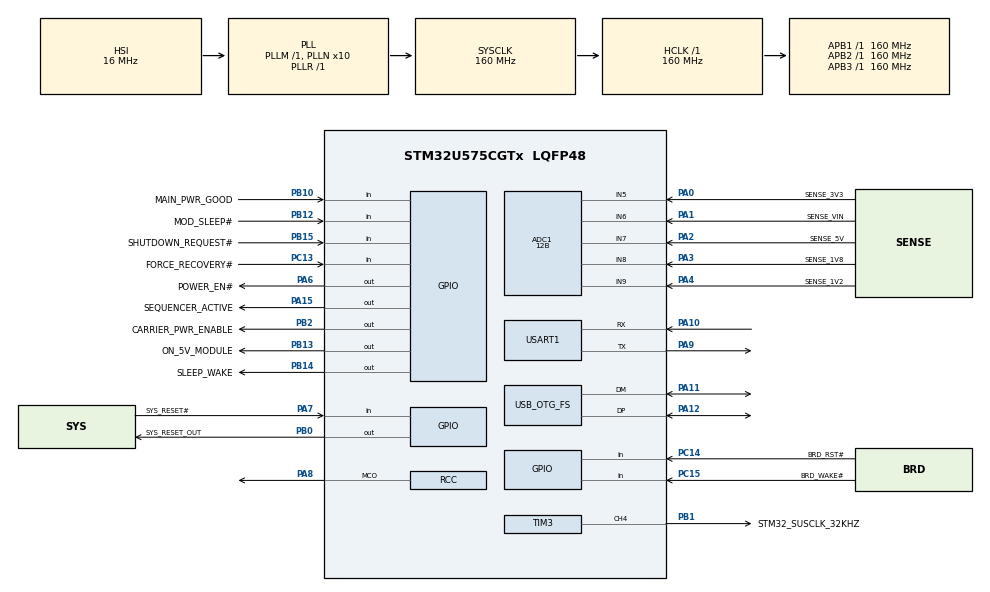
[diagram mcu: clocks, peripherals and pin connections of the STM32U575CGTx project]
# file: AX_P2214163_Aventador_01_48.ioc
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ADC1.Channel-0\#ChannelRegularConversion=ADC_CHANNEL_5
ADC1.Channel-1\#ChannelRegularConversion=ADC_CHANNEL_6
ADC1.Channel-2\#ChannelRegularConversion=ADC_CHANNEL_7
ADC1.Channel-3\#ChannelRegularConversion=ADC_CHANNEL_8
ADC1.Channel-4\#ChannelRegularConversion=ADC_CHANNEL_9
ADC1.ClockPrescaler=ADC_CLOCK_ASYNC_DIV256
ADC1.ContinuousConvMode=DISABLE
ADC1.ConversionDataManagement=ADC_CONVERSIONDATA_DMA_CIRCULAR
ADC1.EOCSelection=ADC_EOC_SEQ_CONV
ADC1.EnableRegularConversion=ENABLE
ADC1.ExternalTrigConv=ADC_EXTERNALTRIG_T6_TRGO
ADC1.MonitoredBy-0\#ChannelRegularConversion=__NULL
ADC1.MonitoredBy-1\#ChannelRegularConversion=__NULL
ADC1.MonitoredBy-2\#ChannelRegularConversion=__NULL
ADC1.MonitoredBy-3\#ChannelRegularConversion=__NULL
ADC1.MonitoredBy-4\#ChannelRegularConversion=__NULL
ADC1.NbrOfConversion=5
ADC1.NbrOfConversionFlag=1
ADC1.OffsetNumber-0\#ChannelRegularConversion=ADC_OFFSET_NONE
ADC1.OffsetNumber-1\#ChannelRegularConversion=ADC_OFFSET_NONE
ADC1.OffsetNumber-2\#ChannelRegularConversion=ADC_OFFSET_NONE
ADC1.OffsetNumber-3\#ChannelRegularConversion=ADC_OFFSET_NONE
ADC1.OffsetNumber-4\#ChannelRegularConversion=ADC_OFFSET_NONE
ADC1.OversamplingMode=ENABLE
ADC1.Rank-0\#ChannelRegularConversion=1
ADC1.Rank-1\#ChannelRegularConversion=2
ADC1.Rank-2\#ChannelRegularConversion=3
ADC1.Rank-3\#ChannelRegularConversion=4
ADC1.Rank-4\#ChannelRegularConversion=5
ADC1.Ratio=8
ADC1.Resolution=ADC_RESOLUTION_12B
ADC1.RightBitShift=ADC_RIGHTBITSHIFT_3
ADC1.SamplingTime-0\#ChannelRegularConversion=ADC_SAMPLETIME_391CYCLES_5
ADC1.SamplingTime-1\#ChannelRegularConversion=ADC_SAMPLETIME_391CYCLES_5
ADC1.SamplingTime-2\#ChannelRegularConversion=ADC_SAMPLETIME_391CYCLES_5
ADC1.SamplingTime-3\#ChannelRegularConversion=ADC_SAMPLETIME_391CYCLES_5
ADC1.SamplingTime-4\#ChannelRegularConversion=ADC_SAMPLETIME_391CYCLES_5
ADC1.master=1
CORTEX_M33_NS.userName=CORTEX_M33
GPDMA1.CIRCULARMODE_GPDMACH0=ENABLE
GPDMA1.DESTDATAWIDTH_GPDMACH0=DMA_DEST_DATAWIDTH_HALFWORD
GPDMA1.DESTINC_GPDMACH0=DMA_DINC_INCREMENTED
GPDMA1.DIRECTION_GPDMACH2=DMA_MEMORY_TO_PERIPH
GPDMA1.IPHANDLE_GPDMACH0-SIMPLEREQUEST_GPDMACH0=__NULL
GPDMA1.IPHANDLE_GPDMACH1-SIMPLEREQUEST_GPDMACH1=__NULL
GPDMA1.IPHANDLE_GPDMACH2-SIMPLEREQUEST_GPDMACH2=__NULL
GPDMA1.REQUEST_GPDMACH0=GPDMA1_REQUEST_ADC1
GPDMA1.REQUEST_GPDMACH1=GPDMA1_REQUEST_USART1_RX
GPDMA1.REQUEST_GPDMACH2=GPDMA1_REQUEST_USART1_TX
GPDMA1.SRCDATAWIDTH_GPDMACH0=DMA_SRC_DATAWIDTH_HALFWORD
GPDMA1.TRANSFERALLOCATEDPORTDEST_GPDMACH2=DMA_DEST_ALLOCATED_PORT1
GPDMA1.TRANSFERALLOCATEDPORTSRC_GPDMACH0=DMA_SRC_ALLOCATED_PORT1
Mcu.Family=STM32U5
Mcu.Name=STM32U575CGTx
Mcu.Package=LQFP48
NVIC.GPDMA1_Channel0_IRQn=true\:0\:0\:false\:false\:true\:false\:true\:true
NVIC.GPDMA1_Channel1_IRQn=true\:0\:0\:false\:false\:true\:false\:true\:true
NVIC.GPDMA1_Channel2_IRQn=true\:0\:0\:false\:false\:true\:false\:true\:true
NVIC.OTG_FS_IRQn=true\:0\:0\:false\:false\:true\:true\:true\:true
NVIC.PriorityGroup=NVIC_PRIORITYGROUP_4
NVIC.TIM6_IRQn=true\:0\:0\:false\:false\:true\:true\:true\:true
NVIC.TIM7_IRQn=true\:0\:0\:false\:false\:true\:true\:true\:true
NVIC.USART1_IRQn=true\:0\:0\:false\:false\:true\:true\:true\:true
PA0.GPIO_Label=SENSE_3V3
PA0.Mode=IN5-Single-Ended
PA0.Signal=ADC1_IN5
PA1.GPIO_Label=SENSE_VIN
PA1.Mode=IN6-Single-Ended
PA1.Signal=ADC1_IN6
PA10.Mode=Asynchronous
PA10.Signal=USART1_RX
PA11.Mode=Device_Only
PA11.Signal=USB_OTG_FS_DM
PA12.Mode=Device_Only
PA12.Signal=USB_OTG_FS_DP
PA13\ (JTMS/SWDIO).Mode=Serial_Wire
PA13\ (JTMS/SWDIO).Signal=DEBUG_JTMS-SWDIO
PA14\ (JTCK/SWCLK).Mode=Serial_Wire
PA14\ (JTCK/SWCLK).Signal=DEBUG_JTCK-SWCLK
PA15\ (JTDI).GPIO_Label=SEQUENCER_ACTIVE
PA15\ (JTDI).Signal=GPIO_Output
PA2.GPIO_Label=SENSE_5V
PA2.Mode=IN7-Single-Ended
PA2.Signal=ADC1_IN7
PA3.GPIO_Label=SENSE_1V8
PA3.Mode=IN8-Single-Ended
PA3.Signal=ADC1_IN8
PA4.GPIO_Label=SENSE_1V2
PA4.Mode=IN9-Single-Ended
PA4.Signal=ADC1_IN9
PA6.GPIO_Label=POWER_EN\#
PA6.PinState=GPIO_PIN_SET
PA6.Signal=GPIO_Output
PA7.GPIO_Label=SYS_RESET\#
PA7.Signal=GPIO_Input
PA8.Mode=Clock-out
PA8.Signal=RCC_MCO
PA9.Mode=Asynchronous
PA9.Signal=USART1_TX
PB0.GPIO_Label=SYS_RESET_OUT
PB0.Signal=GPIO_Output
PB1.GPIO_Label=STM32_SUSCLK_32KHZ
PB1.Signal=S_TIM3_CH4
PB10.GPIO_Label=MAIN_PWR_GOOD
PB10.GPIO_PuPd=GPIO_PULLUP
PB10.Signal=GPIO_Input
PB12.GPIO_Label=MOD_SLEEP\#
PB12.GPIO_PuPd=GPIO_PULLDOWN
PB12.Signal=GPIO_Input
PB13.GPIO_Label=ON_5V_MODULE
PB13.Signal=GPIO_Output
PB14.GPIO_Label=SLEEP_WAKE
PB14.GPIO_ModeDefaultOutputPP=GPIO_MODE_OUTPUT_PP
PB14.GPIO_PuPd=GPIO_NOPULL
PB14.Signal=GPIO_Output
PB15.GPIO_Label=SHUTDOWN_REQUEST\#
PB15.Signal=GPIO_Input
PB2.GPIO_Label=CARRIER_PWR_ENABLE
PB2.Signal=GPIO_Output
PC13.GPIO_Label=FORCE_RECOVERY\#
PC13.GPIO_PuPd=GPIO_PULLUP
PC13.Signal=GPIO_Input
PC14-OSC32_IN\ (PC14).GPIO_Label=BRD_RST\#
PC14-OSC32_IN\ (PC14).GPIO_PuPd=GPIO_PULLUP
PC14-OSC32_IN\ (PC14).Signal=GPIO_Input
PC15-OSC32_OUT\ (PC15).GPIO_Label=BRD_WAKE\#
PC15-OSC32_OUT\ (PC15).GPIO_PuPd=GPIO_PULLUP
PC15-OSC32_OUT\ (PC15).Signal=GPIO_Input
ProjectManager.HeapSize=0x200
ProjectManager.StackSize=0x400
ProjectManager.TargetToolchain=STM32CubeIDE
RCC.ADCFreq_Value=16000000
RCC.AHBFreq_Value=160000000
RCC.APB1Freq_Value=160000000
RCC.APB1TimFreq_Value=160000000
RCC.APB2Freq_Value=160000000
RCC.APB2TimFreq_Value=160000000
RCC.APB3Freq_Value=160000000
RCC.CortexFreq_Value=160000000
RCC.DACCLockSelectionVirtual=RCC_DAC1CLKSOURCE_LSI
RCC.DACCLockSelectionVirtualString=RCC_DAC1CLKSOURCE_LSI
RCC.EPOD_VALUE=16000000
RCC.HCLKFreq_Value=160000000
RCC.HSE_VALUE=24576000
RCC.HSI48_VALUE=48000000
RCC.HSI_VALUE=16000000
RCC.LSE_VALUE=32768
RCC.LSIDIV_VALUE=32000
RCC.MSIClockRange=RCC_MSIRANGE_2
RCC.MSI_VALUE=16000000
RCC.PLL1R=1
RCC.PLLFRACN=0
RCC.PLLN=10
RCC.PLLSourceVirtual=RCC_PLLSOURCE_HSI
RCC.RCC_MCO1SourceVirtual=RCC_MCO1SOURCE_MSI
RCC.SYSCLKFreq_VALUE=160000000
RCC.SYSCLKSource=RCC_SYSCLKSOURCE_PLLCLK
RCC.USBFreq_Value=48000000
RCC.VCOOutputFreq_Value=160000000
SH.S_TIM3_CH4.0=TIM3_CH4,PWM Generation4 CH4
TIM3.Channel-PWM\ Generation4\ CH4=TIM_CHANNEL_4
TIM3.PeriodNoDither=5000
TIM3.PulseNoDither_4=2500
TIM6.PeriodNoDither=10000
TIM6.Prescaler=160
TIM6.TIM_MasterOutputTrigger=TIM_TRGO_UPDATE
TIM7.PeriodNoDither=5000
TIM7.Prescaler=160
USART1.FIFOMode=FIFOMODE_ENABLE
USART1.RXFIFOThreshold=RXFIFO_THRESHOLD_1EIGHTHFULL
USART1.SwapParam=ADVFEATURE_SWAP_ENABLE
USART1.VirtualMode-Asynchronous=VM_ASYNC
USB_OTG_FS.VirtualMode=Device_Only
VP_GPDMA1_VS_GPDMACH0.Mode=SIMPLEREQUEST_GPDMACH0
VP_GPDMA1_VS_GPDMACH1.Mode=SIMPLEREQUEST_GPDMACH1
VP_GPDMA1_VS_GPDMACH2.Mode=SIMPLEREQUEST_GPDMACH2
VP_ICACHE_VS_ICACHE.Mode=DefaultMode
VP_PWR_VS_DBSignals.Mode=DisableDeadBatterySignals
VP_TIM3_VS_ClockSourceINT.Mode=Internal
VP_TIM6_VS_ClockSourceINT.Mode=Enable_Timer
VP_TIM7_VS_ClockSourceINT.Mode=Enable_Timer
board=custom

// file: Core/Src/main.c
/* USER CODE BEGIN Header */
/**
  ******************************************************************************
  * @file           : main.c
  * @brief          : Main program body
  ******************************************************************************
  * @attention
  *
  * Copyright (c) 2023 STMicroelectronics.
  * All rights reserved.
  *
  * This software is licensed under terms that can be found in the LICENSE file
  * in the root directory of this software component.
  * If no LICENSE file comes with this software, it is provided AS-IS.
  *
  ******************************************************************************
  */
/* USER CODE END Header */
#include "main.h"

ADC_HandleTypeDef hadc1;
DMA_NodeTypeDef Node_GPDMA1_Channel0;
DMA_QListTypeDef List_GPDMA1_Channel0;
DMA_HandleTypeDef handle_GPDMA1_Channel0;

TIM_HandleTypeDef htim3;
TIM_HandleTypeDef htim6;
TIM_HandleTypeDef htim7;

UART_HandleTypeDef huart1;
DMA_HandleTypeDef handle_GPDMA1_Channel2;
DMA_HandleTypeDef handle_GPDMA1_Channel1;

PCD_HandleTypeDef hpcd_USB_OTG_FS;

void SystemClock_Config(void);
static void SystemPower_Config(void);
static void MX_GPIO_Init(void);
static void MX_GPDMA1_Init(void);
static void MX_ICACHE_Init(void);
static void MX_ADC1_Init(void);
static void MX_USB_OTG_FS_PCD_Init(void);
static void MX_TIM6_Init(void);
static void MX_TIM3_Init(void);
static void MX_USART1_UART_Init(void);
static void MX_TIM7_Init(void);

int main(void)
{

  /* MCU Configuration--------------------------------------------------------*/

  /* Reset of all peripherals, Initializes the Flash interface and the Systick. */
  HAL_Init();

  /* Configure the system clock */
  SystemClock_Config();

  /* Configure the System Power */
  SystemPower_Config();

  /* Initialize all configured peripherals */
  MX_GPIO_Init();
  MX_GPDMA1_Init();
  MX_ICACHE_Init();
  MX_ADC1_Init();
  MX_USB_OTG_FS_PCD_Init();
  MX_TIM6_Init();
  MX_TIM3_Init();
  MX_USART1_UART_Init();
  MX_TIM7_Init();
  /* USER CODE BEGIN 2 */
  App_Init();
  /* USER CODE END 2 */

  /* Infinite loop */
  /* USER CODE BEGIN WHILE */
  while (1)
  {
	  App_Loop();
    /* USER CODE END WHILE */

  }
}

void SystemClock_Config(void)
{
  RCC_OscInitTypeDef RCC_OscInitStruct = {0};
  RCC_ClkInitTypeDef RCC_ClkInitStruct = {0};

  /** Configure the main internal regulator output voltage
  */
  if (HAL_PWREx_ControlVoltageScaling(PWR_REGULATOR_VOLTAGE_SCALE1) != HAL_OK)
  {
    Error_Handler();
  }

  /** Initializes the CPU, AHB and APB buses clocks
  */
  RCC_OscInitStruct.OscillatorType = RCC_OSCILLATORTYPE_HSI48|RCC_OSCILLATORTYPE_HSI
                              |RCC_OSCILLATORTYPE_MSI;
  RCC_OscInitStruct.HSIState = RCC_HSI_ON;
  RCC_OscInitStruct.HSI48State = RCC_HSI48_ON;
  RCC_OscInitStruct.HSICalibrationValue = RCC_HSICALIBRATION_DEFAULT;
  RCC_OscInitStruct.MSIState = RCC_MSI_ON;
  RCC_OscInitStruct.MSICalibrationValue = RCC_MSICALIBRATION_DEFAULT;
  RCC_OscInitStruct.MSIClockRange = RCC_MSIRANGE_2;
  RCC_OscInitStruct.PLL.PLLState = RCC_PLL_ON;
  RCC_OscInitStruct.PLL.PLLSource = RCC_PLLSOURCE_HSI;
  RCC_OscInitStruct.PLL.PLLMBOOST = RCC_PLLMBOOST_DIV1;
  RCC_OscInitStruct.PLL.PLLM = 1;
  RCC_OscInitStruct.PLL.PLLN = 10;
  RCC_OscInitStruct.PLL.PLLP = 2;
  RCC_OscInitStruct.PLL.PLLQ = 2;
  RCC_OscInitStruct.PLL.PLLR = 1;
  RCC_OscInitStruct.PLL.PLLRGE = RCC_PLLVCIRANGE_1;
  RCC_OscInitStruct.PLL.PLLFRACN = 0;
  if (HAL_RCC_OscConfig(&RCC_OscInitStruct) != HAL_OK)
  {
    Error_Handler();
  }

  /** Initializes the CPU, AHB and APB buses clocks
  */
  RCC_ClkInitStruct.ClockType = RCC_CLOCKTYPE_HCLK|RCC_CLOCKTYPE_SYSCLK
                              |RCC_CLOCKTYPE_PCLK1|RCC_CLOCKTYPE_PCLK2
                              |RCC_CLOCKTYPE_PCLK3;
  RCC_ClkInitStruct.SYSCLKSource = RCC_SYSCLKSOURCE_PLLCLK;
  RCC_ClkInitStruct.AHBCLKDivider = RCC_SYSCLK_DIV1;
  RCC_ClkInitStruct.APB1CLKDivider = RCC_HCLK_DIV1;
  RCC_ClkInitStruct.APB2CLKDivider = RCC_HCLK_DIV1;
  RCC_ClkInitStruct.APB3CLKDivider = RCC_HCLK_DIV1;

  if (HAL_RCC_ClockConfig(&RCC_ClkInitStruct, FLASH_LATENCY_4) != HAL_OK)
  {
    Error_Handler();
  }

  /** MCO configuration
  */
  HAL_RCC_MCOConfig(RCC_MCO1, RCC_MCO1SOURCE_MSI, RCC_MCODIV_1);
}

/**
  * @brief Power Configuration
  * @retval None
  */
static void SystemPower_Config(void)
{

  /*
   * Disable the internal Pull-Up in Dead Battery pins of UCPD peripheral
   */
  HAL_PWREx_DisableUCPDDeadBattery();
}

static void MX_ADC1_Init(void)
{

  ADC_ChannelConfTypeDef sConfig = {0};

  /** Common config
  */
  hadc1.Instance = ADC1;
  hadc1.Init.ClockPrescaler = ADC_CLOCK_ASYNC_DIV256;
  hadc1.Init.Resolution = ADC_RESOLUTION_12B;
  hadc1.Init.GainCompensation = 0;
  hadc1.Init.ScanConvMode = ADC_SCAN_ENABLE;
  hadc1.Init.EOCSelection = ADC_EOC_SEQ_CONV;
  hadc1.Init.LowPowerAutoWait = DISABLE;
  hadc1.Init.ContinuousConvMode = DISABLE;
  hadc1.Init.NbrOfConversion = 5;
  hadc1.Init.DiscontinuousConvMode = DISABLE;
  hadc1.Init.ExternalTrigConv = ADC_EXTERNALTRIG_T6_TRGO;
  hadc1.Init.ExternalTrigConvEdge = ADC_EXTERNALTRIGCONVEDGE_RISING;
  hadc1.Init.DMAContinuousRequests = DISABLE;
  hadc1.Init.TriggerFrequencyMode = ADC_TRIGGER_FREQ_HIGH;
  hadc1.Init.Overrun = ADC_OVR_DATA_PRESERVED;
  hadc1.Init.LeftBitShift = ADC_LEFTBITSHIFT_NONE;
  hadc1.Init.ConversionDataManagement = ADC_CONVERSIONDATA_DMA_CIRCULAR;
  hadc1.Init.OversamplingMode = ENABLE;
  hadc1.Init.Oversampling.Ratio = 8;
  hadc1.Init.Oversampling.RightBitShift = ADC_RIGHTBITSHIFT_3;
  hadc1.Init.Oversampling.TriggeredMode = ADC_TRIGGEREDMODE_SINGLE_TRIGGER;
  hadc1.Init.Oversampling.OversamplingStopReset = ADC_REGOVERSAMPLING_CONTINUED_MODE;
  if (HAL_ADC_Init(&hadc1) != HAL_OK)
  {
    Error_Handler();
  }

  /** Configure Regular Channel
  */
  sConfig.Channel = ADC_CHANNEL_5;
  sConfig.Rank = ADC_REGULAR_RANK_1;
  sConfig.SamplingTime = ADC_SAMPLETIME_391CYCLES_5;
  sConfig.SingleDiff = ADC_SINGLE_ENDED;
  sConfig.OffsetNumber = ADC_OFFSET_NONE;
  sConfig.Offset = 0;
  if (HAL_ADC_ConfigChannel(&hadc1, &sConfig) != HAL_OK)
  {
    Error_Handler();
  }

  /** Configure Regular Channel
  */
  sConfig.Channel = ADC_CHANNEL_6;
  sConfig.Rank = ADC_REGULAR_RANK_2;
  if (HAL_ADC_ConfigChannel(&hadc1, &sConfig) != HAL_OK)
  {
    Error_Handler();
  }

  /** Configure Regular Channel
  */
  sConfig.Channel = ADC_CHANNEL_7;
  sConfig.Rank = ADC_REGULAR_RANK_3;
  if (HAL_ADC_ConfigChannel(&hadc1, &sConfig) != HAL_OK)
  {
    Error_Handler();
  }

  /** Configure Regular Channel
  */
  sConfig.Channel = ADC_CHANNEL_8;
  sConfig.Rank = ADC_REGULAR_RANK_4;
  if (HAL_ADC_ConfigChannel(&hadc1, &sConfig) != HAL_OK)
  {
    Error_Handler();
  }

  /** Configure Regular Channel
  */
  sConfig.Channel = ADC_CHANNEL_9;
  sConfig.Rank = ADC_REGULAR_RANK_5;
  if (HAL_ADC_ConfigChannel(&hadc1, &sConfig) != HAL_OK)
  {
    Error_Handler();
  }

}

static void MX_GPDMA1_Init(void)
{

  /* Peripheral clock enable */
  __HAL_RCC_GPDMA1_CLK_ENABLE();

  /* GPDMA1 interrupt Init */
    HAL_NVIC_SetPriority(GPDMA1_Channel0_IRQn, 0, 0);
    HAL_NVIC_EnableIRQ(GPDMA1_Channel0_IRQn);
    HAL_NVIC_SetPriority(GPDMA1_Channel1_IRQn, 0, 0);
    HAL_NVIC_EnableIRQ(GPDMA1_Channel1_IRQn);
    HAL_NVIC_SetPriority(GPDMA1_Channel2_IRQn, 0, 0);
    HAL_NVIC_EnableIRQ(GPDMA1_Channel2_IRQn);

}

static void MX_ICACHE_Init(void)
{

  /** Enable instruction cache (default 2-ways set associative cache)
  */
  if (HAL_ICACHE_Enable() != HAL_OK)
  {
    Error_Handler();
  }

}

static void MX_TIM3_Init(void)
{

  TIM_ClockConfigTypeDef sClockSourceConfig = {0};
  TIM_MasterConfigTypeDef sMasterConfig = {0};
  TIM_OC_InitTypeDef sConfigOC = {0};

  htim3.Instance = TIM3;
  htim3.Init.Prescaler = 0;
  htim3.Init.CounterMode = TIM_COUNTERMODE_UP;
  htim3.Init.Period = 5000;
  htim3.Init.ClockDivision = TIM_CLOCKDIVISION_DIV1;
  htim3.Init.AutoReloadPreload = TIM_AUTORELOAD_PRELOAD_DISABLE;
  if (HAL_TIM_Base_Init(&htim3) != HAL_OK)
  {
    Error_Handler();
  }
  sClockSourceConfig.ClockSource = TIM_CLOCKSOURCE_INTERNAL;
  if (HAL_TIM_ConfigClockSource(&htim3, &sClockSourceConfig) != HAL_OK)
  {
    Error_Handler();
  }
  if (HAL_TIM_PWM_Init(&htim3) != HAL_OK)
  {
    Error_Handler();
  }
  sMasterConfig.MasterOutputTrigger = TIM_TRGO_RESET;
  sMasterConfig.MasterSlaveMode = TIM_MASTERSLAVEMODE_DISABLE;
  if (HAL_TIMEx_MasterConfigSynchronization(&htim3, &sMasterConfig) != HAL_OK)
  {
    Error_Handler();
  }
  sConfigOC.OCMode = TIM_OCMODE_PWM1;
  sConfigOC.Pulse = 2500;
  sConfigOC.OCPolarity = TIM_OCPOLARITY_HIGH;
  sConfigOC.OCFastMode = TIM_OCFAST_DISABLE;
  if (HAL_TIM_PWM_ConfigChannel(&htim3, &sConfigOC, TIM_CHANNEL_4) != HAL_OK)
  {
    Error_Handler();
  }
  HAL_TIM_MspPostInit(&htim3);

}

static void MX_TIM6_Init(void)
{

  TIM_MasterConfigTypeDef sMasterConfig = {0};

  htim6.Instance = TIM6;
  htim6.Init.Prescaler = 160;
  htim6.Init.CounterMode = TIM_COUNTERMODE_UP;
  htim6.Init.Period = 10000;
  htim6.Init.AutoReloadPreload = TIM_AUTORELOAD_PRELOAD_DISABLE;
  if (HAL_TIM_Base_Init(&htim6) != HAL_OK)
  {
    Error_Handler();
  }
  sMasterConfig.MasterOutputTrigger = TIM_TRGO_UPDATE;
  sMasterConfig.MasterSlaveMode = TIM_MASTERSLAVEMODE_DISABLE;
  if (HAL_TIMEx_MasterConfigSynchronization(&htim6, &sMasterConfig) != HAL_OK)
  {
    Error_Handler();
  }

}

static void MX_TIM7_Init(void)
{

  TIM_MasterConfigTypeDef sMasterConfig = {0};

  htim7.Instance = TIM7;
  htim7.Init.Prescaler = 160;
  htim7.Init.CounterMode = TIM_COUNTERMODE_UP;
  htim7.Init.Period = 5000;
  htim7.Init.AutoReloadPreload = TIM_AUTORELOAD_PRELOAD_DISABLE;
  if (HAL_TIM_Base_Init(&htim7) != HAL_OK)
  {
    Error_Handler();
  }
  sMasterConfig.MasterOutputTrigger = TIM_TRGO_RESET;
  sMasterConfig.MasterSlaveMode = TIM_MASTERSLAVEMODE_DISABLE;
  if (HAL_TIMEx_MasterConfigSynchronization(&htim7, &sMasterConfig) != HAL_OK)
  {
    Error_Handler();
  }

}

static void MX_USART1_UART_Init(void)
{

  huart1.Instance = USART1;
  huart1.Init.BaudRate = 115200;
  huart1.Init.WordLength = UART_WORDLENGTH_8B;
  huart1.Init.StopBits = UART_STOPBITS_1;
  huart1.Init.Parity = UART_PARITY_NONE;
  huart1.Init.Mode = UART_MODE_TX_RX;
  huart1.Init.HwFlowCtl = UART_HWCONTROL_NONE;
  huart1.Init.OverSampling = UART_OVERSAMPLING_16;
  huart1.Init.OneBitSampling = UART_ONE_BIT_SAMPLE_DISABLE;
  huart1.Init.ClockPrescaler = UART_PRESCALER_DIV1;
  huart1.AdvancedInit.AdvFeatureInit = UART_ADVFEATURE_SWAP_INIT;
  huart1.AdvancedInit.Swap = UART_ADVFEATURE_SWAP_ENABLE;
  if (HAL_UART_Init(&huart1) != HAL_OK)
  {
    Error_Handler();
  }
  if (HAL_UARTEx_SetTxFifoThreshold(&huart1, UART_TXFIFO_THRESHOLD_1_8) != HAL_OK)
  {
    Error_Handler();
  }
  if (HAL_UARTEx_SetRxFifoThreshold(&huart1, UART_RXFIFO_THRESHOLD_1_2) != HAL_OK)
  {
    Error_Handler();
  }
  if (HAL_UARTEx_EnableFifoMode(&huart1) != HAL_OK)
  {
    Error_Handler();
  }

}

static void MX_USB_OTG_FS_PCD_Init(void)
{

  hpcd_USB_OTG_FS.Instance = USB_OTG_FS;
  hpcd_USB_OTG_FS.Init.dev_endpoints = 6;
  hpcd_USB_OTG_FS.Init.phy_itface = PCD_PHY_EMBEDDED;
  hpcd_USB_OTG_FS.Init.Sof_enable = DISABLE;
  hpcd_USB_OTG_FS.Init.low_power_enable = DISABLE;
  hpcd_USB_OTG_FS.Init.lpm_enable = DISABLE;
  hpcd_USB_OTG_FS.Init.battery_charging_enable = DISABLE;
  hpcd_USB_OTG_FS.Init.use_dedicated_ep1 = DISABLE;
  hpcd_USB_OTG_FS.Init.vbus_sensing_enable = DISABLE;
  if (HAL_PCD_Init(&hpcd_USB_OTG_FS) != HAL_OK)
  {
    Error_Handler();
  }

}

static void MX_GPIO_Init(void)
{
  GPIO_InitTypeDef GPIO_InitStruct = {0};

  /* GPIO Ports Clock Enable */
  __HAL_RCC_GPIOC_CLK_ENABLE();
  __HAL_RCC_GPIOA_CLK_ENABLE();
  __HAL_RCC_GPIOB_CLK_ENABLE();

  /*Configure GPIO pin Output Level */
  HAL_GPIO_WritePin(POWER_EN__GPIO_Port, POWER_EN__Pin, GPIO_PIN_SET);

  /*Configure GPIO pin Output Level */
  HAL_GPIO_WritePin(GPIOB, SYS_RESET_OUT_Pin|CARRIER_PWR_ENABLE_Pin|ON_5V_MODULE_Pin|SLEEP_WAKE_Pin, GPIO_PIN_RESET);

  /*Configure GPIO pin Output Level */
  HAL_GPIO_WritePin(SEQUENCER_ACTIVE_GPIO_Port, SEQUENCER_ACTIVE_Pin, GPIO_PIN_RESET);

  /*Configure GPIO pins : FORCE_RECOVERY__Pin BRD_RST__Pin BRD_WAKE__Pin */
  GPIO_InitStruct.Pin = FORCE_RECOVERY__Pin|BRD_RST__Pin|BRD_WAKE__Pin;
  GPIO_InitStruct.Mode = GPIO_MODE_INPUT;
  GPIO_InitStruct.Pull = GPIO_PULLUP;
  HAL_GPIO_Init(GPIOC, &GPIO_InitStruct);

  /*Configure GPIO pins : POWER_EN__Pin SEQUENCER_ACTIVE_Pin */
  GPIO_InitStruct.Pin = POWER_EN__Pin|SEQUENCER_ACTIVE_Pin;
  GPIO_InitStruct.Mode = GPIO_MODE_OUTPUT_PP;
  GPIO_InitStruct.Pull = GPIO_NOPULL;
  GPIO_InitStruct.Speed = GPIO_SPEED_FREQ_LOW;
  HAL_GPIO_Init(GPIOA, &GPIO_InitStruct);

  /*Configure GPIO pin : SYS_RESET__Pin */
  GPIO_InitStruct.Pin = SYS_RESET__Pin;
  GPIO_InitStruct.Mode = GPIO_MODE_INPUT;
  GPIO_InitStruct.Pull = GPIO_NOPULL;
  HAL_GPIO_Init(SYS_RESET__GPIO_Port, &GPIO_InitStruct);

  /*Configure GPIO pins : SYS_RESET_OUT_Pin CARRIER_PWR_ENABLE_Pin ON_5V_MODULE_Pin SLEEP_WAKE_Pin */
  GPIO_InitStruct.Pin = SYS_RESET_OUT_Pin|CARRIER_PWR_ENABLE_Pin|ON_5V_MODULE_Pin|SLEEP_WAKE_Pin;
  GPIO_InitStruct.Mode = GPIO_MODE_OUTPUT_PP;
  GPIO_InitStruct.Pull = GPIO_NOPULL;
  GPIO_InitStruct.Speed = GPIO_SPEED_FREQ_LOW;
  HAL_GPIO_Init(GPIOB, &GPIO_InitStruct);

  /*Configure GPIO pin : MAIN_PWR_GOOD_Pin */
  GPIO_InitStruct.Pin = MAIN_PWR_GOOD_Pin;
  GPIO_InitStruct.Mode = GPIO_MODE_INPUT;
  GPIO_InitStruct.Pull = GPIO_PULLUP;
  HAL_GPIO_Init(MAIN_PWR_GOOD_GPIO_Port, &GPIO_InitStruct);

  /*Configure GPIO pin : MOD_SLEEP__Pin */
  GPIO_InitStruct.Pin = MOD_SLEEP__Pin;
  GPIO_InitStruct.Mode = GPIO_MODE_INPUT;
  GPIO_InitStruct.Pull = GPIO_PULLDOWN;
  HAL_GPIO_Init(MOD_SLEEP__GPIO_Port, &GPIO_InitStruct);

  /*Configure GPIO pin : SHUTDOWN_REQUEST__Pin */
  GPIO_InitStruct.Pin = SHUTDOWN_REQUEST__Pin;
  GPIO_InitStruct.Mode = GPIO_MODE_INPUT;
  GPIO_InitStruct.Pull = GPIO_NOPULL;
  HAL_GPIO_Init(SHUTDOWN_REQUEST__GPIO_Port, &GPIO_InitStruct);

  /*Configure GPIO pin : PA8 */
  GPIO_InitStruct.Pin = GPIO_PIN_8;
  GPIO_InitStruct.Mode = GPIO_MODE_AF_PP;
  GPIO_InitStruct.Pull = GPIO_NOPULL;
  GPIO_InitStruct.Speed = GPIO_SPEED_FREQ_HIGH;
  GPIO_InitStruct.Alternate = GPIO_AF0_MCO;
  HAL_GPIO_Init(GPIOA, &GPIO_InitStruct);

}

void Error_Handler(void)
{
  __disable_irq();
  while (1)
  {
  }
}
